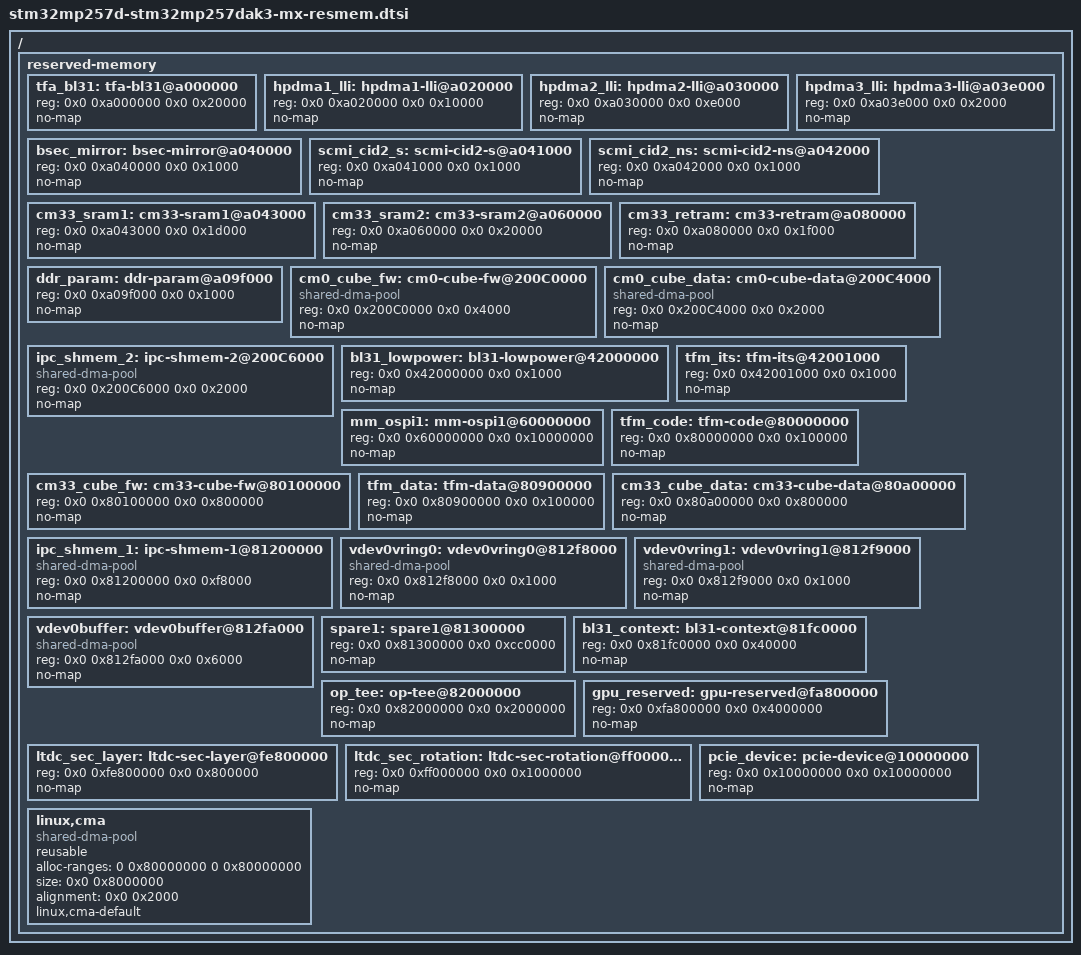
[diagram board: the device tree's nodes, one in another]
// SPDX-License-Identifier: (GPL-2.0-only OR BSD-3-Clause)
/*
 * Copyright (C) 2026, STMicroelectronics - All Rights Reserved
 * Author: STM32CubeMX code generation for STMicroelectronics.
 */

/* For more information on Device Tree configuration, please refer to
 * https://wiki.st.com/stm32mpu/wiki/Category:Device_tree_configuration
 */

/ {
	reserved-memory {
		#address-cells = <2>;
		#size-cells = <2>;
		ranges;

		/* USER CODE BEGIN reserved-memory */
		/*Applicative memory mapping can be defined in this section deduced from OP-TEE one*/
		tfa_bl31: tfa-bl31@a000000 {
			reg = <0x0 0xa000000 0x0 0x20000>;
			no-map;

			/* USER CODE BEGIN tfa_bl31 */
			/* USER CODE END tfa_bl31 */
		};

		hpdma1_lli: hpdma1-lli@a020000 {
			reg = <0x0 0xa020000 0x0 0x10000>;
			no-map;

			/* USER CODE BEGIN hpdma1_lli */
			/* USER CODE END hpdma1_lli */
		};

		hpdma2_lli: hpdma2-lli@a030000 {
			reg = <0x0 0xa030000 0x0 0xe000>;
			no-map;

			/* USER CODE BEGIN hpdma2_lli */
			/* USER CODE END hpdma2_lli */
		};

		hpdma3_lli: hpdma3-lli@a03e000 {
			reg = <0x0 0xa03e000 0x0 0x2000>;
			no-map;

			/* USER CODE BEGIN hpdma3_lli */
			/* USER CODE END hpdma3_lli */
		};

		bsec_mirror: bsec-mirror@a040000 {
			reg = <0x0 0xa040000 0x0 0x1000>;
			no-map;

			/* USER CODE BEGIN bsec_mirror */
			/* USER CODE END bsec_mirror */
		};

		scmi_cid2_s: scmi-cid2-s@a041000 {
			reg = <0x0 0xa041000 0x0 0x1000>;
			no-map;

			/* USER CODE BEGIN scmi_cid2_s */
			/* USER CODE END scmi_cid2_s */
		};

		scmi_cid2_ns: scmi-cid2-ns@a042000 {
			reg = <0x0 0xa042000 0x0 0x1000>;
			no-map;

			/* USER CODE BEGIN scmi_cid2_ns */
			/* USER CODE END scmi_cid2_ns */
		};

		cm33_sram1: cm33-sram1@a043000 {
			reg = <0x0 0xa043000 0x0 0x1d000>;
			no-map;

			/* USER CODE BEGIN cm33_sram1 */
			/* USER CODE END cm33_sram1 */
		};

		cm33_sram2: cm33-sram2@a060000 {
			reg = <0x0 0xa060000 0x0 0x20000>;
			no-map;

			/* USER CODE BEGIN cm33_sram2 */
			/* USER CODE END cm33_sram2 */
		};

		cm33_retram: cm33-retram@a080000 {
			reg = <0x0 0xa080000 0x0 0x1f000>;
			no-map;

			/* USER CODE BEGIN cm33_retram */
			/* USER CODE END cm33_retram */
		};

		ddr_param: ddr-param@a09f000 {
			reg = <0x0 0xa09f000 0x0 0x1000>;
			no-map;

			/* USER CODE BEGIN ddr_param */
			/* USER CODE END ddr_param */
		};

		cm0_cube_fw: cm0-cube-fw@200C0000 {
			compatible = "shared-dma-pool";
			reg = <0x0 0x200C0000 0x0 0x4000>;
			no-map;
		};

		cm0_cube_data: cm0-cube-data@200C4000 {
			compatible = "shared-dma-pool";
			reg = <0x0 0x200C4000 0x0 0x2000>;
			no-map;
		};

		ipc_shmem_2: ipc-shmem-2@200C6000{
			compatible = "shared-dma-pool";
			reg = <0x0 0x200C6000 0x0 0x2000>;
			no-map;
		};

		bl31_lowpower: bl31-lowpower@42000000 {
			reg = <0x0 0x42000000 0x0 0x1000>;
			no-map;

			/* USER CODE BEGIN bl31_lowpower */
			/* USER CODE END bl31_lowpower */
		};

		tfm_its: tfm-its@42001000 {
			reg = <0x0 0x42001000 0x0 0x1000>;
			no-map;

			/* USER CODE BEGIN tfm_its */
			/* USER CODE END tfm_its */
		};

		mm_ospi1: mm-ospi1@60000000 {
			reg = <0x0 0x60000000 0x0 0x10000000>;
			no-map;

			/* USER CODE BEGIN mm_ospi1 */
			/* USER CODE END mm_ospi1 */
		};

		tfm_code: tfm-code@80000000 {
			reg = <0x0 0x80000000 0x0 0x100000>;
			no-map;

			/* USER CODE BEGIN tfm_code */
			/* USER CODE END tfm_code */
		};

		cm33_cube_fw: cm33-cube-fw@80100000 {
			reg = <0x0 0x80100000 0x0 0x800000>;
			no-map;

			/* USER CODE BEGIN cm33_cube_fw */
			/* USER CODE END cm33_cube_fw */
		};

		tfm_data: tfm-data@80900000 {
			reg = <0x0 0x80900000 0x0 0x100000>;
			no-map;

			/* USER CODE BEGIN tfm_data */
			/* USER CODE END tfm_data */
		};

		cm33_cube_data: cm33-cube-data@80a00000 {
			reg = <0x0 0x80a00000 0x0 0x800000>;
			no-map;

			/* USER CODE BEGIN cm33_cube_data */
			/* USER CODE END cm33_cube_data */
		};

		ipc_shmem_1: ipc-shmem-1@81200000 {
			compatible = "shared-dma-pool";
			reg = <0x0 0x81200000 0x0 0xf8000>;
			no-map;
		};


		vdev0vring0: vdev0vring0@812f8000 {
			compatible = "shared-dma-pool";
			reg = <0x0 0x812f8000 0x0 0x1000>;
			no-map;
		};

		vdev0vring1: vdev0vring1@812f9000 {
			compatible = "shared-dma-pool";
			reg = <0x0 0x812f9000 0x0 0x1000>;
			no-map;
		};

		vdev0buffer: vdev0buffer@812fa000 {
			compatible = "shared-dma-pool";
			reg = <0x0 0x812fa000 0x0 0x6000>;
			no-map;
		};

		spare1: spare1@81300000 {
			reg = <0x0 0x81300000 0x0 0xcc0000>;
			no-map;

			/* USER CODE BEGIN spare1 */
			/* USER CODE END spare1 */
		};

		bl31_context: bl31-context@81fc0000 {
			reg = <0x0 0x81fc0000 0x0 0x40000>;
			no-map;

			/* USER CODE BEGIN bl31_context */
			/* USER CODE END bl31_context */
		};

		op_tee: op-tee@82000000 {
			reg = <0x0 0x82000000 0x0 0x2000000>;
			no-map;

			/* USER CODE BEGIN op_tee */
			/* USER CODE END op_tee */
		};

		gpu_reserved: gpu-reserved@fa800000 {
			reg = <0x0 0xfa800000 0x0 0x4000000>;
			no-map;

			/* USER CODE BEGIN gpu_reserved */
			/* USER CODE END gpu_reserved */
		};


		ltdc_sec_layer: ltdc-sec-layer@fe800000 {
			reg = <0x0 0xfe800000 0x0 0x800000>;
			no-map;

			/* USER CODE BEGIN ltdc_sec_layer */
			/* USER CODE END ltdc_sec_layer */
		};

		ltdc_sec_rotation: ltdc-sec-rotation@ff000000 {
			reg = <0x0 0xff000000 0x0 0x1000000>;
			no-map;

			/* USER CODE BEGIN ltdc_sec_rotation */
			/* USER CODE END ltdc_sec_rotation */
		};

		pcie_device: pcie-device@10000000 {
			reg = <0x0 0x10000000 0x0 0x10000000>;
			no-map;

			/* USER CODE BEGIN pcie_device */
			/* USER CODE END pcie_device */
		};
		
		/* global autoconfigured region for contiguous allocations */
		linux,cma {
			compatible = "shared-dma-pool";
			reusable;
			alloc-ranges = <0 0x80000000 0 0x80000000>;
			size = <0x0 0x8000000>;
			alignment = <0x0 0x2000>;
			linux,cma-default;
		};
		/* USER CODE END reserved-memory */
	};
};
